# RockChip_RK3588 register map
Vendor: RockChip Electronics Co., Ltd.; Series: RK3588; File version: 0.1
Registers are 32-bit, read-write, no defined reset value unless marked. A register's access mark holds for its fields unless they carry their own. Offsets are from the block's base; [hi:lo] are bit positions; {n}, {i} and the like mark numbered series.

## IOC_VCCIO2
Base 0xFD5FB000
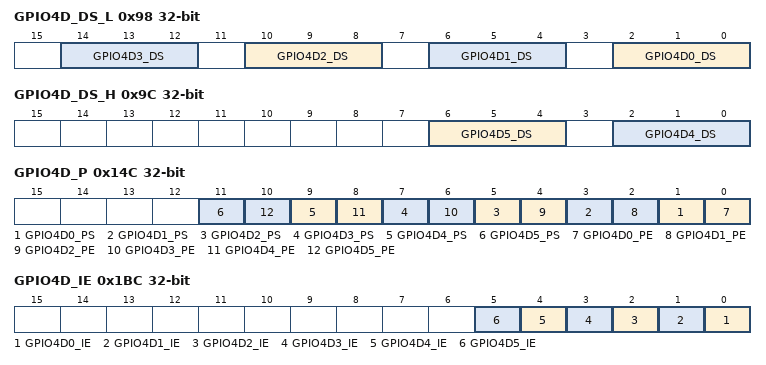
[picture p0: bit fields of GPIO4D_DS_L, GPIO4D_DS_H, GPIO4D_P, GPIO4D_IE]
0x98 GPIO4D_DS_L — GPIO4D Driver Strength Control Low bits
  [all] fields
    0=100OHM; 4=66OHM; 2=50OHM; 6=40OHM; 1=33OHM; 5=25OHM
  [4n+2:4n] GPIO4D{n}_DS (n=0..3) — GPIO4D{n} DS control Driver Strength Selection
0x9C GPIO4D_DS_H — GPIO4D Driver Strength Control High bits
  [6:4] GPIO4D5_DS — GPIO4D5 DS control Driver Strength Selection
    0=100OHM; 4=66OHM; 2=50OHM; 6=40OHM; 1=33OHM; 5=25OHM
  [2:0] GPIO4D4_DS — GPIO4D4 DS control Driver Strength Selection
    0=100OHM; 4=66OHM; 2=50OHM; 6=40OHM; 1=33OHM; 5=25OHM
0x14C GPIO4D_P — GPIO4D Pull-up/down Control
  [2n+1] GPIO4D{n}_PS (n=0..5) — GPIO4D{n} PS control Weak PU/PD Resistor Selection
    0=PD_SELECTION; 1=PU_SELECTION
  [2n] GPIO4D{n}_PE (n=0..5) — GPIO4D{n} PE control Active High Weak PU/PD Resistor Enable
    0=PU_PD_DISABLE; 1=PU_PD_ENABLE
0x1BC GPIO4D_IE — GPIO4D Input Enable Control
  [all] fields
    1=ENABLE; 0=DISABLE
  [n] GPIO4D{n}_IE (n=0..5) — GPIO4D{n} IE control Active High input buffer enable
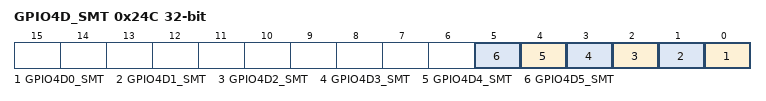
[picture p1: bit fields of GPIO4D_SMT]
0x24C GPIO4D_SMT — GPIO4D Schmitt Trigger Control
  [all] fields
    0=CMOS; 1=SCHMITT_TRIGGER
  [n] GPIO4D{n}_SMT (n=0..5) — GPIO4D{n} SMT control CMOS/Schmitt Trigger Selection
0x284 GPIO_PDIS — Auto Pull-up/down disable Control
  [0] VCCIO2_PULL_DIS
    1=DISABLE (disable VCCIO2 GPIO pull up/down when output enable)

## IOC_VCCIO6
Base 0xFD5FC000
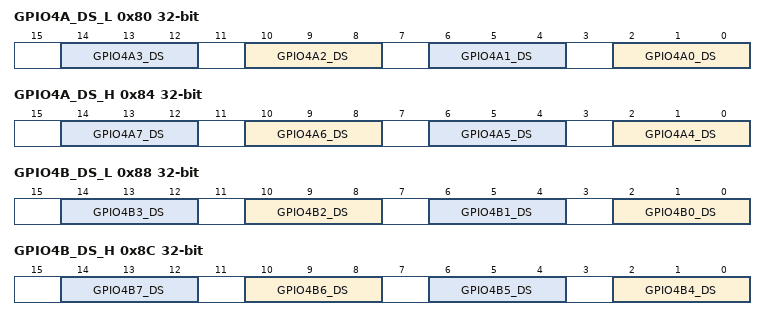
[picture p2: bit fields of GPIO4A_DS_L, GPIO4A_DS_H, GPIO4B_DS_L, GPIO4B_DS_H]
0x80 GPIO4A_DS_L — GPIO4A Driver Strength Control Low bits
  [all] fields
    0=100OHM; 4=66OHM; 2=50OHM; 6=40OHM; 1=33OHM; 5=25OHM
  [4n+2:4n] GPIO4A{n}_DS (n=0..3) — GPIO4A{n} DS control Driver Strength Selection
0x84 GPIO4A_DS_H — GPIO4A Driver Strength Control High bits
  [all] fields
    0=100OHM; 4=66OHM; 2=50OHM; 6=40OHM; 1=33OHM; 5=25OHM
  [4n-14:4n-16] GPIO4A{n}_DS (n=4..7) — GPIO4A{n} DS control Driver Strength Selection
0x88 GPIO4B_DS_L — GPIO4B Driver Strength Control Low bits
  [all] fields
    0=100OHM; 4=66OHM; 2=50OHM; 6=40OHM; 1=33OHM; 5=25OHM
  [4n+2:4n] GPIO4B{n}_DS (n=0..3) — GPIO4B{n} DS control Driver Strength Selection
0x8C GPIO4B_DS_H — GPIO4B Driver Strength Control High bits
  [all] fields
    0=100OHM; 4=66OHM; 2=50OHM; 6=40OHM; 1=33OHM; 5=25OHM
  [4n-14:4n-16] GPIO4B{n}_DS (n=4..7) — GPIO4B{n} DS control Driver Strength Selection
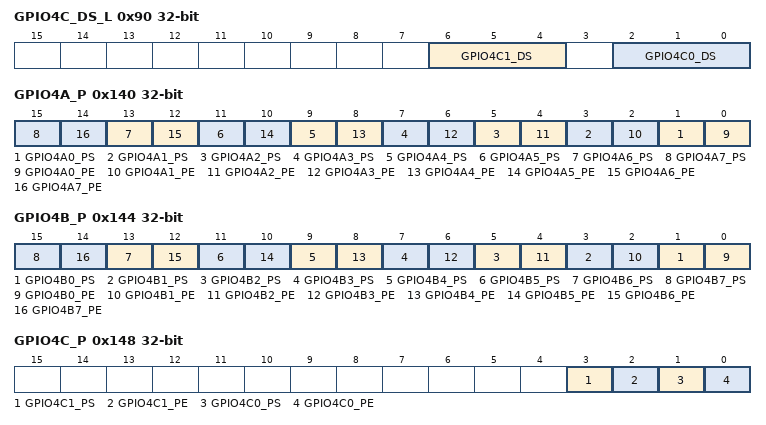
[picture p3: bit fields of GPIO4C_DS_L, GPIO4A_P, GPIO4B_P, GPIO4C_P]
0x90 GPIO4C_DS_L — GPIO4C Driver Strength Control Low bits
  [6:4] GPIO4C1_DS — GPIO4C1 DS control Driver Strength Selection
    0=100OHM; 4=66OHM; 2=50OHM; 6=40OHM; 1=33OHM; 5=25OHM
  [2:0] GPIO4C0_DS — GPIO4C0 DS control Driver Strength Selection
    0=100OHM; 4=66OHM; 2=50OHM; 6=40OHM; 1=33OHM; 5=25OHM
0x140 GPIO4A_P — GPIO4A Pull-up/down Control
  [2n+1] GPIO4A{n}_PS (n=0..7) — GPIO4A{n} PS control Weak PU/PD Resistor Selection
    0=PD_SELECTION; 1=PU_SELECTION
  [2n] GPIO4A{n}_PE (n=0..7) — GPIO4A{n} PE control Active High Weak PU/PD Resistor Enable
    0=PU_PD_DISABLE; 1=PU_PD_ENABLE
0x144 GPIO4B_P — GPIO4B Pull-up/down Control
  [2n+1] GPIO4B{n}_PS (n=0..7) — GPIO4B{n} PS control Weak PU/PD Resistor Selection
    0=PD_SELECTION; 1=PU_SELECTION
  [2n] GPIO4B{n}_PE (n=0..7) — GPIO4B{n} PE control Active High Weak PU/PD Resistor Enable
    0=PU_PD_DISABLE; 1=PU_PD_ENABLE
0x148 GPIO4C_P — GPIO4C Pull-up/down Control
  [3] GPIO4C1_PS — GPIO4C1 PS control Weak PU/PD Resistor Selection
    0=PD_SELECTION; 1=PU_SELECTION
  [2] GPIO4C1_PE — GPIO4C1 PE control Active High Weak PU/PD Resistor Enable
    0=PU_PD_DISABLE; 1=PU_PD_ENABLE
  [1] GPIO4C0_PS — GPIO4C0 PS control Weak PU/PD Resistor Selection
    0=PD_SELECTION; 1=PU_SELECTION
  [0] GPIO4C0_PE — GPIO4C0 PE control Active High Weak PU/PD Resistor Enable
    0=PU_PD_DISABLE; 1=PU_PD_ENABLE
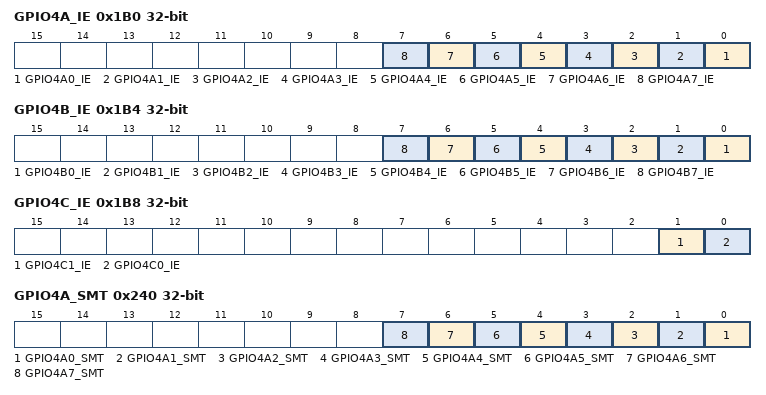
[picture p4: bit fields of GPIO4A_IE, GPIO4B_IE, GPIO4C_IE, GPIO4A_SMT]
0x1B0 GPIO4A_IE — GPIO4A Input Enable Control
  [all] fields
    1=ENABLE; 0=DISABLE
  [n] GPIO4A{n}_IE (n=0..7) — GPIO4A{n} IE control Active High input buffer enable
0x1B4 GPIO4B_IE — GPIO4B Input Enable Control
  [all] fields
    1=ENABLE; 0=DISABLE
  [n] GPIO4B{n}_IE (n=0..7) — GPIO4B{n} IE control Active High input buffer enable
0x1B8 GPIO4C_IE — GPIO4C Input Enable Control
  [1] GPIO4C1_IE — GPIO4C1 IE control Active High input buffer enable
    1=ENABLE; 0=DISABLE
  [0] GPIO4C0_IE — GPIO4C0 IE control Active High input buffer enable
    1=ENABLE; 0=DISABLE
0x240 GPIO4A_SMT — GPIO4A Schmitt Trigger Control
  [all] fields
    0=CMOS; 1=SCHMITT_TRIGGER
  [n] GPIO4A{n}_SMT (n=0..7) — GPIO4A{n} SMT control CMOS/Schmitt Trigger Selection
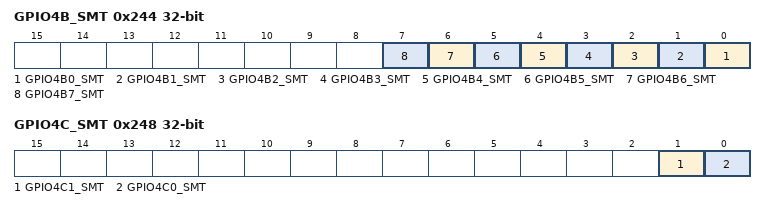
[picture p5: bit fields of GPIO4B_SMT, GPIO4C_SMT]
0x244 GPIO4B_SMT — GPIO4B Schmitt Trigger Control
  [all] fields
    0=CMOS; 1=SCHMITT_TRIGGER
  [n] GPIO4B{n}_SMT (n=0..7) — GPIO4B{n} SMT control CMOS/Schmitt Trigger Selection
0x248 GPIO4C_SMT — GPIO4C Schmitt Trigger Control
  [1] GPIO4C1_SMT — GPIO4C1 SMT control CMOS/Schmitt Trigger Selection
    0=CMOS; 1=SCHMITT_TRIGGER
  [0] GPIO4C0_SMT — GPIO4C0 SMT control CMOS/Schmitt Trigger Selection
    0=CMOS; 1=SCHMITT_TRIGGER
0x28C GPIO_PDIS — Auto Pull-up/down disable Control
  [0] VCCIO6_PULL_DIS
    1=DISABLE (disable VCCIO6 GPIO pull up/down when output enable)
